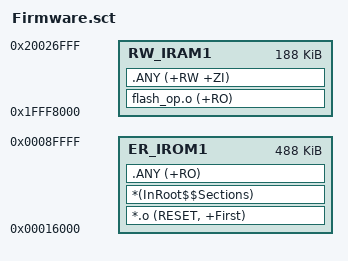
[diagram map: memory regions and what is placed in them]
; *************************************************************
; *** Scatter-Loading Description File generated by uVision ***
; *************************************************************
; OTA: App 链接基址 0x16000（boot run_app 跳转地址），512KB 片内减 boot 区

LR_IROM1 0x00016000 0x0007A000  {    ; load region size_region (App@0x16000, 488KB)
  ER_IROM1 0x00016000 0x0007A000  {  ; load address = execution address
   *.o (RESET, +First)
   *(InRoot$$Sections)
   .ANY (+RO)
  }
  RW_IRAM1 0x1FFF8000 0x0002F000  {  ; RW data
    flash_op.o (+RO)
   .ANY (+RW +ZI)
  }
}
